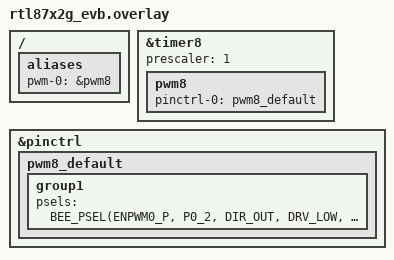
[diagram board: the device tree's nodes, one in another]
/*
 * Copyright(c) 2025, Realtek Semiconductor Corporation.
 *
 * SPDX-License-Identifier: Apache-2.0
 */

#include <zephyr/dt-bindings/pwm/pwm.h>

/ {
	aliases {
		pwm-0 = &pwm8;
	};
};

&timer8 {
	status = "okay";
	prescaler = <1>;
	pwm8: pwm8 {
		status = "okay";
		pinctrl-0 = <&pwm8_default>;
		pinctrl-names = "default";
	};
};

&pinctrl {
	pwm8_default: pwm8_default {
		group1 {
			psels = <BEE_PSEL(ENPWM0_P, P0_2, DIR_OUT, DRV_LOW, PULL_DOWN)>;
		};
	};
};
